# STM32WL5x_CM4 register map
File version: 1.9
CPU: CM4 r0p1, little endian, MPU, FPU, 4 interrupt priority bits
Registers are 32-bit, read-write, reset 0x0 unless marked. A register's access mark holds for its fields unless they carry their own. Offsets are from the block's base; [hi:lo] are bit positions.

## IWDG — Independent watchdog
Base 0x40003000
0x00 KR wo — Key register
  [15:0] KEY — Key value (write only, read 0x0000)
0x04 PR reset 0x7 — Prescaler register
  [2:0] PR — Prescaler divider
0x08 RLR reset 0xFFF — Reload register
  [11:0] RL — Watchdog counter reload value
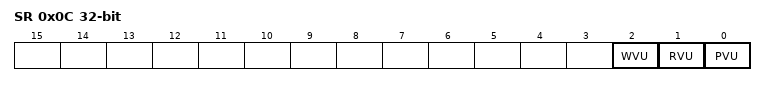
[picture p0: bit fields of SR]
0x0C SR ro — Status register
  [2] WVU — Watchdog counter window value update
  [1] RVU — Watchdog counter reload value update
  [0] PVU — Watchdog prescaler value update
0x10 WINR reset 0xFFF — Window register
  [11:0] WIN — Watchdog counter window value

## LPTIM1 — Low-power timer
Base 0x40007C00
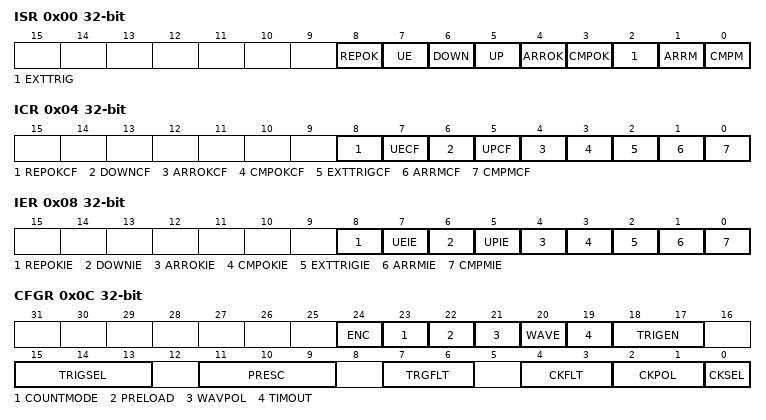
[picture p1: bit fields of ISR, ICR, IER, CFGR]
0x00 ISR ro — interrupt and status register
  [8] REPOK — Repetition register update Ok
  [7] UE — LPTIM update event occurred
  [6] DOWN — Counter direction change up to down
  [5] UP — Counter direction change down to up
  [4] ARROK — Autoreload register update OK
  [3] CMPOK — Compare register update OK
  [2] EXTTRIG — External trigger edge event
  [1] ARRM — Autoreload match
  [0] CMPM — Compare match
0x04 ICR wo — interrupt clear register
  [8] REPOKCF — Repetition register update OK clear flag
  [7] UECF — Update event clear flag
  [6] DOWNCF — Direction change to down Clear Flag
  [5] UPCF — Direction change to UP Clear Flag
  [4] ARROKCF — Autoreload register update OK Clear Flag
  [3] CMPOKCF — Compare register update OK Clear Flag
  [2] EXTTRIGCF — External trigger valid edge Clear Flag
  [1] ARRMCF — Autoreload match Clear Flag
  [0] CMPMCF — compare match Clear Flag
0x08 IER — interrupt enable register
  [8] REPOKIE — Repetition register update OK interrupt Enable
  [7] UEIE — Update event interrupt enable
  [6] DOWNIE — Direction change to down Interrupt Enable
  [5] UPIE — Direction change to UP Interrupt Enable
  [4] ARROKIE — Autoreload register update OK Interrupt Enable
  [3] CMPOKIE — Compare register update OK Interrupt Enable
  [2] EXTTRIGIE — External trigger valid edge Interrupt Enable
  [1] ARRMIE — Autoreload match Interrupt Enable
  [0] CMPMIE — Compare match Interrupt Enable
0x0C CFGR — configuration register
  [24] ENC, [23] COUNTMODE, [22] PRELOAD, [21] WAVPOL, [20] WAVE, [19] TIMOUT, [18:17] TRIGEN, [15:13] TRIGSEL, [11:9] PRESC, [7:6] TRGFLT, [4:3] CKFLT, [2:1] CKPOL, [0] CKSEL
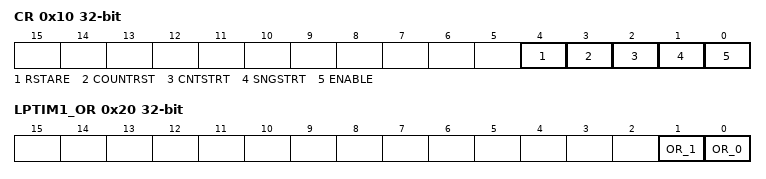
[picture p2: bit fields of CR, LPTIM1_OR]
0x10 CR — control register
  [4] RSTARE, [3] COUNTRST, [2] CNTSTRT, [1] SNGSTRT, [0] ENABLE
0x14 CMP — compare register
  [15:0] CMP
0x18 ARR reset 0x1 — autoreload register
  [15:0] ARR — Auto reload value
0x1C CNT ro — counter register
  [15:0] CNT — Counter value
0x20 LPTIM1_OR — option register
  [1] OR_1 — Option register bit 1
  [0] OR_0 — Option register bit 0
0x28 RCR — repetition register
  [7:0] REP — Repetition register value

## LPTIM2 — Low-power timer
Base 0x40009400
Registers as LPTIM1 (with LPTIM1 read as LPTIM2).

## LPTIM3 — Low-power timer
Base 0x40009800
Registers as LPTIM1 (with LPTIM1 read as LPTIM3).

## MPU — Memory protection unit
Base 0xE000ED90
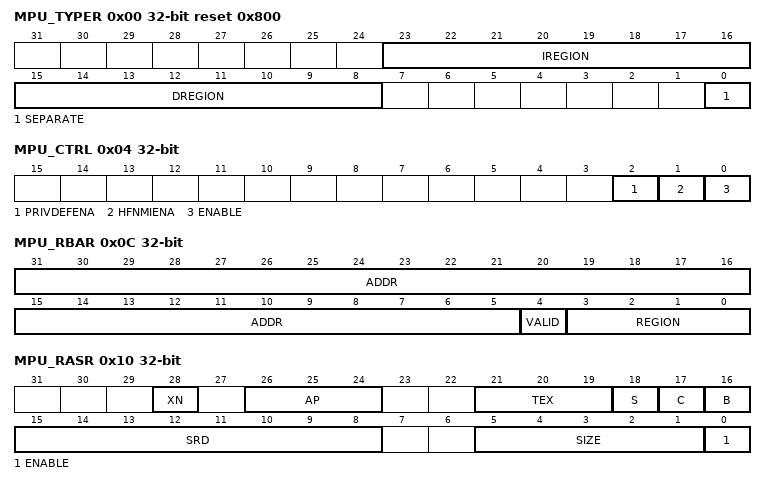
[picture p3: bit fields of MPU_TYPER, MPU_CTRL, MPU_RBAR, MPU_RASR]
0x00 MPU_TYPER ro reset 0x800 — MPU type register
  [23:16] IREGION — Number of MPU instruction regions
  [15:8] DREGION — Number of MPU data regions
  [0] SEPARATE — Separate flag
0x04 MPU_CTRL ro — MPU control register
  [2] PRIVDEFENA — Enable priviliged software access to default memory map
  [1] HFNMIENA — Enables the operation of MPU during hard fault
  [0] ENABLE — Enables the MPU
0x08 MPU_RNR — MPU region number register
  [7:0] REGION — MPU region
0x0C MPU_RBAR — MPU region base address register
  [31:5] ADDR — Region base address field
  [4] VALID — MPU region number valid
  [3:0] REGION — MPU region field
0x10 MPU_RASR — MPU region attribute and size register
  [28] XN — Instruction access disable bit
  [26:24] AP — Access permission
  [21:19] TEX — memory attribute
  [18] S — Shareable memory attribute
  [17] C — memory attribute
  [16] B — memory attribute
  [15:8] SRD — Subregion disable bits
  [5:1] SIZE — Size of the MPU protection region
  [0] ENABLE — Region enable bit.
